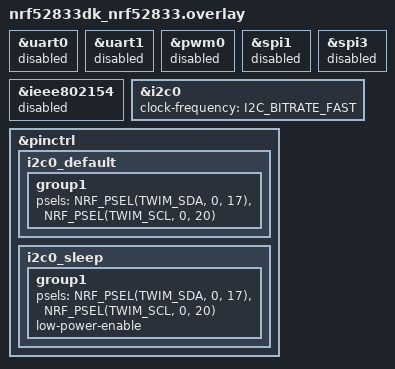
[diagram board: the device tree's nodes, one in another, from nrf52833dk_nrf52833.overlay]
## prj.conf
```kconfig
# enable SoC DC/DC for better power consumption (default y)
CONFIG_BOARD_ENABLE_DCDC=y

# enable Floating Point Unit (default n?)
CONFIG_FPU=y
# enable FPU sharing (multiple threads at once can use FPU)
CONFIG_FPU_SHARING=y

#CONFIG_CONSOLE=y
#CONFIG_USE_SEGGER_RTT=y
#CONFIG_RTT_CONSOLE=y
#CONFIG_LOG=y
#CONFIG_LOG_SPEED=y

CONFIG_I2C=y

# need below for math
CONFIG_NEWLIB_LIBC=y

CONFIG_BT=y
CONFIG_BT_PERIPHERAL=y
CONFIG_BT_DEVICE_NAME="TTPMS External Sensor"
CONFIG_BT_DEVICE_NAME_DYNAMIC=y
#CONFIG_BT_DEVICE_NAME_MAX default is 28 chars which will be fine
CONFIG_BT_DEVICE_APPEARANCE=1362

CONFIG_BT_BUF_ACL_TX_SIZE=251
CONFIG_BT_BUF_ACL_RX_SIZE=251
CONFIG_BT_L2CAP_TX_MTU=247
CONFIG_BT_CTLR_DATA_LENGTH_MAX=251

# set TX power to max (+8dB)
CONFIG_BT_CTLR_TX_PWR_PLUS_8=y
```

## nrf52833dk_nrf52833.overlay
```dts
// To get started, press Ctrl+Space to bring up the completion menu and view the available nodes.

// You can also use the buttons in the sidebar to perform actions on nodes.
// Actions currently available include:

// * Enabling / disabling the node
// * Adding the bus to a bus
// * Removing the node
// * Connecting ADC channels

// For more help, browse the DeviceTree documentation at https://docs.zephyrproject.org/latest/guides/dts/index.html
// You can also visit the nRF DeviceTree extension documentation at https://nrfconnect.github.io/vscode-nrf-connect/devicetree/nrfdevicetree.html


/* disabling all unused peripherals */

&uart0 {
    status = "disabled";
};

&uart1 {
    status = "disabled";
};

&pwm0 {
    status = "disabled";
};

&spi1 {
    status = "disabled";
};

&spi3 {
    status = "disabled";
};

&ieee802154 {
    status = "disabled";
};


/* configuring peripherals we will use  */

&i2c0 {
    status = "okay";
    clock-frequency = <I2C_BITRATE_FAST>; // 400KHz
};

// ADC etc

&pinctrl {
    i2c0_default: i2c0_default {
		group1 {
			psels = <NRF_PSEL(TWIM_SDA, 0, 17)>,
				    <NRF_PSEL(TWIM_SCL, 0, 20)>;    // ttpms_exm_2_0 uses P0.14 but this is an LED on the DK
		};
	};

	i2c0_sleep: i2c0_sleep {
		group1 {
			psels = <NRF_PSEL(TWIM_SDA, 0, 17)>,
				    <NRF_PSEL(TWIM_SCL, 0, 20)>;    // ttpms_exm_2_0 uses P0.14 but this is an LED on the DK
			low-power-enable;
		};
	};
};
```

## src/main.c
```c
/* includes that will always be required */
#include <zephyr/kernel.h>
#include <zephyr/types.h>
#include <stddef.h>
#include <errno.h>
#include <zephyr/bluetooth/bluetooth.h>
#include <zephyr/bluetooth/hci.h>
#include <zephyr/bluetooth/conn.h>
#include <zephyr/bluetooth/uuid.h>
#include <zephyr/bluetooth/gatt.h>
#include <zephyr/drivers/gpio.h>
#include <math.h>

#include "ttpms_common.h"
#include "I2C_Functions.h"
#include "MLX90640_API.h"

/* includes for debugging/temporary */
#include <zephyr/logging/log.h>

LOG_MODULE_REGISTER(ttpms);


// IMPORTANT: define which corner the sensor will go
// options = TTPMS_EFL or TTPMS_EFR
#define TTPMS_EFL


// frequency of temp sensor updates (0x00 = 0.5Hz, 0x01 = 1Hz, 0x02 = 2Hz, 0x03 = 4Hz, 0x04 = 8Hz, 0x05 = 16Hz (default), 0x06 = 32Hz, 0x07 = 64Hz)
// note that only one subpage is updated. 8Hz (0x04) seems to be the limit for NRF52833. 40ms required for I2C transmission, 60ms for processing
// if upgraded to NRF5340, we could go to 1MHz I2C and also process faster
// best way forward is to modify the MLX90640_API.c functions to only read and process relevant pixels
#define TEMP_FREQ 0x04


// haven't tuned these
#define TEMP_THREAD_STACKSIZE 8192
#define TEMP_THREAD_PRIORITY 4

void temp_thread(void *dummy1, void *dummy2, void *dummy3);
K_THREAD_STACK_DEFINE(temp_stack_area, TEMP_THREAD_STACKSIZE);
struct k_thread temp_thread_data;
k_tid_t temp_thread_id;


// How we keep track of state.
// Use Zephyr atomic set, clear, test functions.
ATOMIC_DEFINE(flags, 1);
#define TEMP_ENABLED_FLAG 0


// The actual temp data we will send to receiver
// Temp values have 0.5 scale, 0 offset (ie 0xAF = 175 = 87.5 C)
uint8_t tire_temp[32];


// Tune the below with testing
const float ta_shift = 8;			// Default shift for MLX90641 in open air
const float emissivity = 0.95;	// Tune this with testing


static float mlx90640To[MLX90640_PIXEL_NUM];	// Processed temp data from MLX functions
paramsMLX90640 mlx90640;	// Used for MLX functions

float Vdd;	// From MLX, used by MLX functions
float Ta;	// From MLX, used by MLX functions


static const struct gpio_dt_spec mlx_power =
	GPIO_DT_SPEC_GET_OR(DT_NODELABEL(mlx_power), gpios, {0});


/* --- BLUETOOTH SHIT START --- */

#define BLE_ADV_INTERVAL_MIN 1200	// 1200 * 0.625ms = 0.75s
#define BLE_ADV_INTERVAL_MAX 2000	// 2000 * 0.625ms = 1.25s

#ifdef TTPMS_EFL
	#define TTPMS_SENSOR_BT_ID TTPMS_EFL_BT_ID
	char bt_device_name[28] = "TTPMS External Sensor FL";
#endif
#ifdef TTPMS_EFR
	#define TTPMS_SENSOR_BT_ID TTPMS_EFR_BT_ID
	char bt_device_name[28] = "TTPMS External Sensor FR";
#endif


static struct bt_uuid_128 primary_service_uuid = BT_UUID_INIT_128(TTPMS_SERVICE_BASE_UUID);
static struct bt_uuid_128 temp_characteristic_uuid = BT_UUID_INIT_128(TTPMS_SERVICE_TEMP_UUID);


static struct bt_le_adv_param adv_param;

static struct bt_conn *connection;


// this is a callback for if CCC is changed (could be subscribe or unsubscribe)
static void subscribe_temp(const struct bt_gatt_attr *attr, uint16_t value)
{
	const bool notif_enabled = (value == BT_GATT_CCC_NOTIFY);	// not sure why this is assigned to this of just checked in the if()

	if (notif_enabled) {	
		atomic_set_bit(flags, TEMP_ENABLED_FLAG);	// enable temperature measurements and start temp thread
		temp_thread_id = k_thread_create(&temp_thread_data, temp_stack_area,
                                 K_THREAD_STACK_SIZEOF(temp_stack_area),
                                 temp_thread,
                                 NULL, NULL, NULL,
                                 TEMP_THREAD_PRIORITY, 0, K_NO_WAIT);
		LOG_INF("Notifications subscribed, temp enabled");
	} else {
		atomic_clear_bit(flags, TEMP_ENABLED_FLAG); // disable temperature measurements
		LOG_INF("Notifications unsubscribed, temp disabled");
	}
}


// Primary Service Declaration
BT_GATT_SERVICE_DEFINE(primary_service,
	BT_GATT_PRIMARY_SERVICE(&primary_service_uuid),
		BT_GATT_CHARACTERISTIC(&temp_characteristic_uuid.uuid, BT_GATT_CHRC_NOTIFY, NULL, NULL, NULL, NULL),
			BT_GATT_CCC(subscribe_temp, BT_GATT_PERM_READ | BT_GATT_PERM_WRITE),
);

static const struct bt_data ad[] = {
	BT_DATA_BYTES(BT_DATA_FLAGS, (BT_LE_AD_GENERAL | BT_LE_AD_NO_BREDR)),
	BT_DATA_BYTES(BT_DATA_UUID128_ALL, TTPMS_SERVICE_BASE_UUID),
};

static void connected(struct bt_conn *conn, uint8_t err)
{
	if (err) {
		LOG_WRN("Connection failed (err 0x%02x)", err);
	} else {
		LOG_INF("Connected");
		connection = conn;
	}
}

static void disconnected(struct bt_conn *conn, uint8_t reason)
{
	LOG_INF("Disconnected (reason 0x%02x)", reason);
	atomic_clear_bit(flags, TEMP_ENABLED_FLAG);	// disable temperature measurements
	connection = NULL;
}

BT_CONN_CB_DEFINE(conn_callbacks) = {
	.connected = connected,
	.disconnected = disconnected
};

/* --- BLUETOOTH SHIT END --- */


void main(void)
{
	LOG_INF("Running ttpms_v2_external_front on %s", CONFIG_BOARD);

	int err;

	if (!gpio_is_ready_dt(&mlx_power)) {
		LOG_ERR("The load switch pin GPIO port is not ready.");
		return;
	}

	err = gpio_pin_configure_dt(&mlx_power, GPIO_OUTPUT_INACTIVE);
	if (err != 0) {
		LOG_ERR("Configuring GPIO pin failed: %d", err);
		return;
	}

	bt_addr_le_t addr;

	err = bt_addr_le_from_str(TTPMS_SENSOR_BT_ID, "random", &addr);
	if (err) {
		LOG_ERR("Invalid BT address (err %d)", err);
	}

	err = bt_id_create(&addr, NULL);
	if (err < 0) {
		LOG_ERR("Creating new BT ID failed (err %d)", err);
	}

	err = bt_enable(NULL);
	if (err) {
		LOG_ERR("Bluetooth init failed (err %d)", err);
	} else {
		LOG_INF("Bluetooth initialized");
	}

	err = bt_set_name(bt_device_name);
	if (err) {
		LOG_ERR("Failed to set BT Device name (err %d)", err);
	} else {
		LOG_INF("Successfully set BT device name");
	}

	adv_param = *BT_LE_ADV_CONN_NAME;
	adv_param.interval_min = BLE_ADV_INTERVAL_MIN;
	adv_param.interval_max = BLE_ADV_INTERVAL_MAX;

	err = bt_le_adv_start(&adv_param, ad, ARRAY_SIZE(ad), NULL, 0);
	if (err) {
		LOG_ERR("Advertising failed to start (err %d)", err);
	} else {
		LOG_INF("Advertising successfully started");
	}

}


void temp_thread(void *dummy1, void *dummy2, void *dummy3)
{
	ARG_UNUSED(dummy1);
	ARG_UNUSED(dummy2);
	ARG_UNUSED(dummy3);

	int status;

	status = gpio_pin_set_dt(&mlx_power, 1);	// turn on MLX power MOSFET
	if (status != 0) {
		LOG_ERR("Setting GPIO pin level failed: %d", status);
	}

	//k_sleep(K_MSEC(80));	// wait 80ms after MLX90640 POR, then:
	//k_sleep(K_MSEC(500));	// wait one refresh rate? default refresh rate?
	k_sleep(K_MSEC(1000));	//datasheet is weird so just wait 1 second to be safe

	uint16_t eeMLX90640[MLX90640_EEPROM_DUMP_NUM];

	status = MLX90640_DumpEE(MLX90640_ADDR, eeMLX90640);
	if (status != 0) {
		LOG_ERR("Failed to load system parameters, MLX90640_DumpEE() returned %d", status);
	} else {
		LOG_INF("Dumped MLX EE");
	}

	status = MLX90640_ExtractParameters(eeMLX90640, &mlx90640);
	if (status != 0) {
		LOG_ERR("Parameter extraction failed, MLX90640_ExtractParameters() returned %d", status);
	} else {
		LOG_INF("Extracted MLX parameters");
	}

	status = MLX90640_SetRefreshRate(MLX90640_ADDR, TEMP_FREQ);
	if (status != 0) {
		LOG_ERR("Setting refresh rate failed, MLX90640_SetRefreshRate() returned %d", status);
	} else {
		LOG_INF("Set MLX refresh rate");
	}

	status = MLX90640_SynchFrame(MLX90640_ADDR);
	if (status != 0) {
		LOG_ERR("Synchronizing MLX frame failed, MLX90640_SynchFrame() returned %d", status);
	} else {
		LOG_INF("Synchronized MLX frame");
	}

	
	while (atomic_test_bit(flags, TEMP_ENABLED_FLAG))	// atomic babbyyyy
	{

		uint16_t frame[834];

		status = MLX90640_GetFrameData(MLX90640_ADDR, frame);	// this function waits until data is available from MLX
		if (status < 0) {
			LOG_ERR("Getting MLX frame data failed, MLX90640_GetFrameData() returned %d", status);
		}

		Vdd = MLX90640_GetVdd(frame, &mlx90640);

		Ta = MLX90640_GetTa(frame, &mlx90640);

		float tr = Ta - ta_shift; // Reflected temperature based on the sensor ambient temperature

		//LOG_INF("started temp processing");
		MLX90640_CalculateTo(frame, &mlx90640, emissivity, tr, mlx90640To);
		//LOG_INF("finished temp processing");

		for (int i = 0; i < 32; i++)
		{
			tire_temp[i] = CLAMP(round((mlx90640To[320+i]+mlx90640To[352+i]+mlx90640To[384+i]+mlx90640To[416+i])/2), 0, 255);
		}
		
		//LOG_INF("First pixel: %.1f 16th pixel: %.1f 32nd pixel: %.1f", ((float)tire_temp[0]/2), ((float)tire_temp[15]/2), ((float)tire_temp[31]/2));

		if((connection != NULL) && atomic_test_bit(flags, TEMP_ENABLED_FLAG)) {	// MLX processing above takes a while, check if we are still connected and temp is enabled
			status = bt_gatt_notify(connection, &primary_service.attrs[1], &tire_temp, sizeof(tire_temp));
			if(status != 0) {
				LOG_ERR("Failed to notify, bt_gatt_notify returned: %d", status);
			} else {
				//LOG_INF("Notified");
			}
		}
	}

	status = gpio_pin_set_dt(&mlx_power, 0);	// turn off MLX power MOSFET
	if (status != 0) {
		LOG_ERR("Setting GPIO pin level failed: %d", status);
	}

}
```

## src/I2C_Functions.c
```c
#include "I2C_Functions.h"
#include <zephyr/kernel.h>
#include <zephyr/device.h>
#include <zephyr/drivers/i2c.h>
#include <errno.h>

/* includes for debugging/temporary */
#include <zephyr/logging/log.h>

LOG_MODULE_DECLARE(ttpms);

const struct device *const i2c_dev = DEVICE_DT_GET(DT_NODELABEL(i2c0)); // should prob change this to i2c chosen (and add the chosen part to devicetree)


void I2C_Init()
{   
    if(!device_is_ready(i2c_dev)) {
        LOG_WRN("Error initializing I2C");
    } else {
        LOG_INF("I2C initialized");
    }
    //i2c_configure should be uneccessary since we set 400KHz in devicetree
}

int I2C_GeneralReset(void)  // this function is originally for MLX one-shot mode, will not be used
{    
    int ack;
    uint8_t cmd = 0x06;   
 
    // writing 0x06 to address 0x00 will reset all devices on I2C
    ack = i2c_write(i2c_dev, &cmd, 1, 0x00);

    if (ack != 0x00)
    {
        LOG_ERR("Error sending I2C reset message");
        return -1;
    }         

    k_sleep(K_USEC(50));    // idk why this sleep is here (from now-deleted Melexis driver sample)

    return 0;
}

int MLX_I2CRead(uint8_t slaveAddr, uint16_t startAddress, uint16_t nMemAddressRead, uint16_t *data)
{                          
    int ack = 0;                               
    int cnt = 0;
    int i = 0;
    char cmd[2] = {0,0};
    char i2cData[1664] = {0};
    uint16_t *p;

    p = data;
    cmd[0] = startAddress >> 8;
    cmd[1] = startAddress & 0x00FF;

    ack = i2c_write_read(i2c_dev, slaveAddr, cmd, 2, i2cData, 2*nMemAddressRead);

    if (ack != 0x00)
    {
        LOG_ERR("Error reading from MLX over I2C");
        return -1;
    }

    for(cnt=0; cnt < nMemAddressRead; cnt++)    // this just turns uint8_t[2*nMemAddressRead] into uint16_t[nMemAddressRead]
    {
        i = cnt << 1;
        *p++ = (uint16_t)i2cData[i]*256 + (uint16_t)i2cData[i+1];
    }

    return 0;   
} 

int MLX_I2CWrite(uint8_t slaveAddr, uint16_t writeAddress, uint16_t data)
{
    int ack = 0;
    char cmd[4] = {0,0,0,0};
    static uint16_t dataCheck;

    cmd[0] = writeAddress >> 8;
    cmd[1] = writeAddress & 0x00FF;
    cmd[2] = data >> 8;
    cmd[3] = data & 0x00FF;

    //k_sleep(K_USEC(5));

    ack = i2c_write(i2c_dev, cmd, 4, slaveAddr);

    if (ack != 0x00)
    {
        //LOG_ERR("Error writing to MLX over I2C");
        return -1;
    }         

    MLX_I2CRead(slaveAddr, writeAddress, 1, &dataCheck);

    if (dataCheck != data)
    {
        //LOG_ERR("Error writing to MLX, readback failed");
        //LOG_ERR("dataCheck: %d  data: %d", dataCheck, data);
        return -2;
    }    

    return 0;
}
```

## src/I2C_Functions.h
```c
#ifndef _I2C_Functions_H_
#define _I2C_Functions_H_

#include <stdint.h>

    extern void I2C_Init(void);
    extern int I2C_GeneralReset(void);
    extern int MLX_I2CRead(uint8_t slaveAddr,uint16_t startAddress, uint16_t nMemAddressRead, uint16_t *data);
    extern int MLX_I2CWrite(uint8_t slaveAddr,uint16_t writeAddress, uint16_t data);
    
    #define MLX90641_ADDR   0x33
    #define MLX90640_ADDR   0x33
    #define MLX90621_ADDR   0x60

#endif
```

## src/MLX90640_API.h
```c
/**
 * @copyright (C) 2017 Melexis N.V.
 *
 * Licensed under the Apache License, Version 2.0 (the "License");
 * you may not use this file except in compliance with the License.
 * You may obtain a copy of the License at
 *
 *     http://www.apache.org/licenses/LICENSE-2.0
 *
 * Unless required by applicable law or agreed to in writing, software
 * distributed under the License is distributed on an "AS IS" BASIS,
 * WITHOUT WARRANTIES OR CONDITIONS OF ANY KIND, either express or implied.
 * See the License for the specific language governing permissions and
 * limitations under the License.
 *
 */
#ifndef _MLX90640_API_H_
#define _MLX90640_API_H_

#define MLX90640_NO_ERROR 0
#define MLX90640_I2C_NACK_ERROR 1
#define MLX90640_I2C_WRITE_ERROR 2
#define MLX90640_BROKEN_PIXELS_NUM_ERROR 3
#define MLX90640_OUTLIER_PIXELS_NUM_ERROR 4
#define MLX90640_BAD_PIXELS_NUM_ERROR 5
#define MLX90640_ADJACENT_BAD_PIXELS_ERROR 6
#define MLX90640_EEPROM_DATA_ERROR 7
#define MLX90640_FRAME_DATA_ERROR 8
#define MLX90640_MEAS_TRIGGER_ERROR 9

#define MLX_BIT_MASK(x) (1UL << (x))
#define REG_MASK(sbit,nbits) ~((~(~0UL << (nbits))) << (sbit))

#define MLX90640_EEPROM_START_ADDRESS 0x2400
#define MLX90640_EEPROM_DUMP_NUM 832
#define MLX90640_PIXEL_DATA_START_ADDRESS 0x0400
#define MLX90640_PIXEL_NUM 768
#define MLX90640_LINE_NUM 24
#define MLX90640_COLUMN_NUM 32
#define MLX90640_LINE_SIZE 32
#define MLX90640_COLUMN_SIZE 24
#define MLX90640_AUX_DATA_START_ADDRESS 0x0700
#define MLX90640_AUX_NUM 64
#define MLX90640_STATUS_REG 0x8000
#define MLX90640_INIT_STATUS_VALUE 0x0030
#define MLX90640_STAT_FRAME_MASK MLX_BIT_MASK(0) 
#define MLX90640_GET_FRAME(reg_value) (reg_value & MLX90640_STAT_FRAME_MASK)
#define MLX90640_STAT_DATA_READY_MASK MLX_BIT_MASK(3) 
#define MLX90640_GET_DATA_READY(reg_value) (reg_value & MLX90640_STAT_DATA_READY_MASK)

#define MLX90640_CTRL_REG 0x800D
#define MLX90640_CTRL_TRIG_READY_MASK MLX_BIT_MASK(15) 
#define MLX90640_CTRL_REFRESH_SHIFT 7
#define MLX90640_CTRL_REFRESH_MASK REG_MASK(MLX90640_CTRL_REFRESH_SHIFT,3)
#define MLX90640_CTRL_RESOLUTION_SHIFT 10
#define MLX90640_CTRL_RESOLUTION_MASK REG_MASK(MLX90640_CTRL_RESOLUTION_SHIFT,2)
#define MLX90640_CTRL_MEAS_MODE_SHIFT 12
#define MLX90640_CTRL_MEAS_MODE_MASK MLX_BIT_MASK(12)

#define MLX90640_MS_BYTE_SHIFT 8
#define MLX90640_MS_BYTE_MASK 0xFF00
#define MLX90640_LS_BYTE_MASK 0x00FF
#define MLX90640_MS_BYTE(reg16) ((reg16 & MLX90640_MS_BYTE_MASK) >> MLX90640_MS_BYTE_SHIFT)
#define MLX90640_LS_BYTE(reg16) (reg16 & MLX90640_LS_BYTE_MASK)
#define MLX90640_MSBITS_6_MASK 0xFC00
#define MLX90640_LSBITS_10_MASK 0x03FF
#define MLX90640_NIBBLE1_MASK 0x000F
#define MLX90640_NIBBLE2_MASK 0x00F0
#define MLX90640_NIBBLE3_MASK 0x0F00
#define MLX90640_NIBBLE4_MASK 0xF000
#define MLX90640_NIBBLE1(reg16) ((reg16 & MLX90640_NIBBLE1_MASK))
#define MLX90640_NIBBLE2(reg16) ((reg16 & MLX90640_NIBBLE2_MASK) >> 4)
#define MLX90640_NIBBLE3(reg16) ((reg16 & MLX90640_NIBBLE3_MASK) >> 8)
#define MLX90640_NIBBLE4(reg16) ((reg16 & MLX90640_NIBBLE4_MASK) >> 12)

#define POW2(x) pow(2, (double)x) 

#define SCALEALPHA 0.000001
    
typedef struct
    {
        int16_t kVdd;
        int16_t vdd25;
        float KvPTAT;
        float KtPTAT;
        uint16_t vPTAT25;
        float alphaPTAT;
        int16_t gainEE;
        float tgc;
        float cpKv;
        float cpKta;
        uint8_t resolutionEE;
        uint8_t calibrationModeEE;
        float KsTa;
        float ksTo[5];
        int16_t ct[5];
        uint16_t alpha[768];    
        uint8_t alphaScale;
        int16_t offset[768];    
        int8_t kta[768];
        uint8_t ktaScale;    
        int8_t kv[768];
        uint8_t kvScale;
        float cpAlpha[2];
        int16_t cpOffset[2];
        float ilChessC[3]; 
        uint16_t brokenPixels[5];
        uint16_t outlierPixels[5];  
    } paramsMLX90640;
    
    int MLX90640_DumpEE(uint8_t slaveAddr, uint16_t *eeData);
    int MLX90640_SynchFrame(uint8_t slaveAddr);
    //int MLX90640_TriggerMeasurement(uint8_t slaveAddr); We will not be using one shot mode
    int MLX90640_GetFrameData(uint8_t slaveAddr, uint16_t *frameData);
    int MLX90640_ExtractParameters(uint16_t *eeData, paramsMLX90640 *mlx90640);
    float MLX90640_GetVdd(uint16_t *frameData, const paramsMLX90640 *params);
    float MLX90640_GetTa(uint16_t *frameData, const paramsMLX90640 *params);
    void MLX90640_GetImage(uint16_t *frameData, const paramsMLX90640 *params, float *result);
    void MLX90640_CalculateTo(uint16_t *frameData, const paramsMLX90640 *params, float emissivity, float tr, float *result);
    int MLX90640_SetResolution(uint8_t slaveAddr, uint8_t resolution);
    int MLX90640_GetCurResolution(uint8_t slaveAddr);
    int MLX90640_SetRefreshRate(uint8_t slaveAddr, uint8_t refreshRate);   
    int MLX90640_GetRefreshRate(uint8_t slaveAddr);  
    int MLX90640_GetSubPageNumber(uint16_t *frameData);
    int MLX90640_GetCurMode(uint8_t slaveAddr); 
    int MLX90640_SetInterleavedMode(uint8_t slaveAddr);
    int MLX90640_SetChessMode(uint8_t slaveAddr);
    void MLX90640_BadPixelsCorrection(uint16_t *pixels, float *to, int mode, paramsMLX90640 *params);
    
#endif
```
